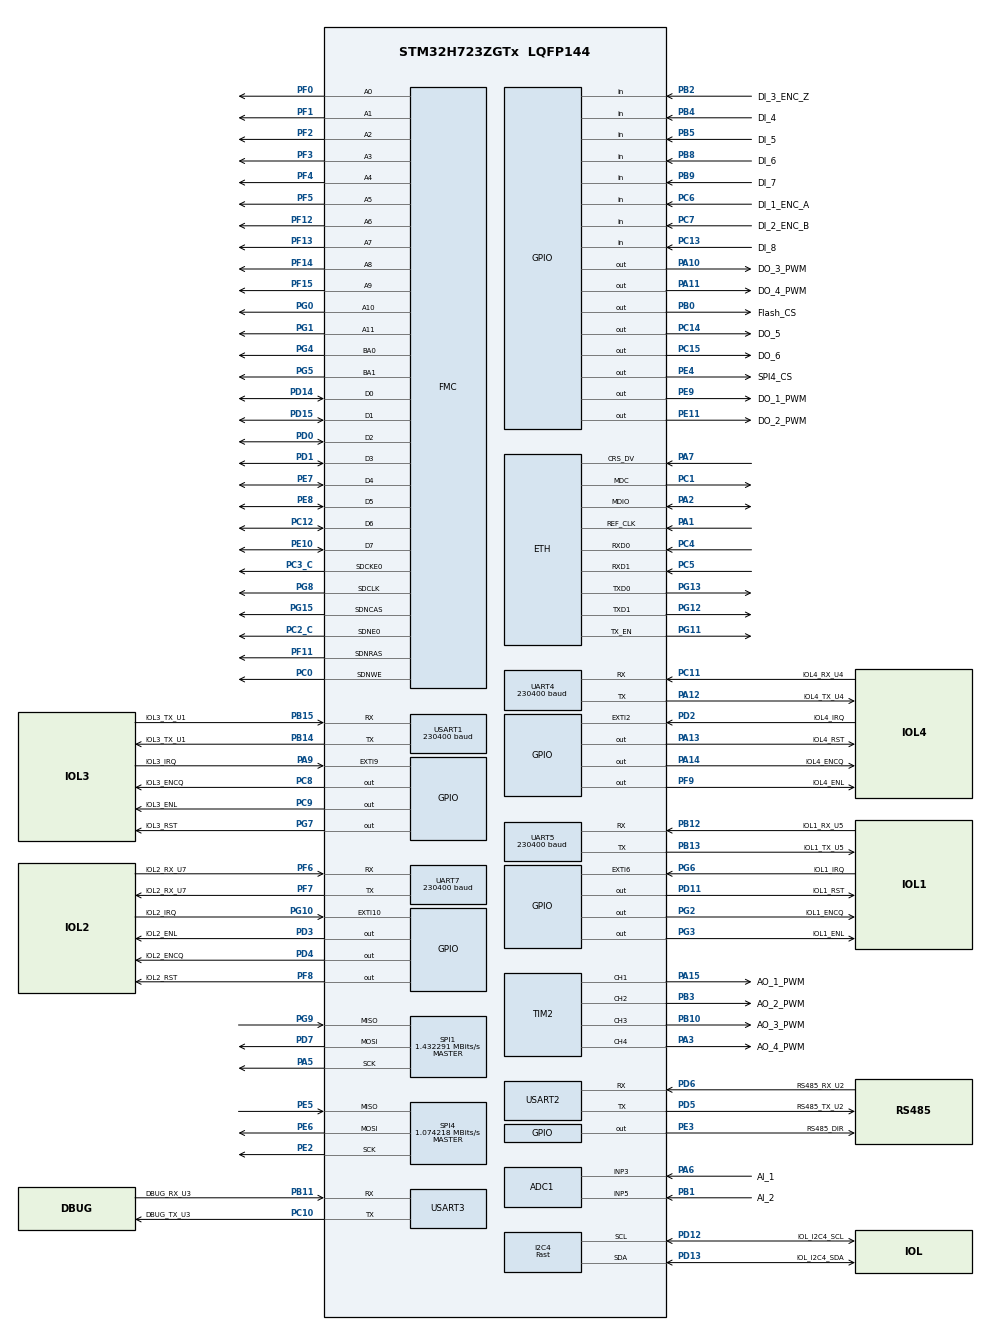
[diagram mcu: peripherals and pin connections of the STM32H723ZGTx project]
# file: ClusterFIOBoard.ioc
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ADC1.Channel-0\#ChannelRegularConversion=ADC_CHANNEL_3
ADC1.NbrOfConversionFlag=1
ADC1.OffsetNumber-0\#ChannelRegularConversion=ADC_OFFSET_NONE
ADC1.OffsetSignedSaturation-0\#ChannelRegularConversion=DISABLE
ADC1.Rank-0\#ChannelRegularConversion=1
ADC1.SamplingTime-0\#ChannelRegularConversion=ADC_SAMPLETIME_1CYCLE_5
ADC1.master=1
CORTEX_M7.CPU_DCache=Enabled
Dma.Request0=SPI4_TX
Dma.Request1=SPI4_RX
Dma.Request2=SPI1_TX
Dma.Request3=SPI1_RX
Dma.SPI1_RX.3.Direction=DMA_PERIPH_TO_MEMORY
Dma.SPI1_RX.3.EventEnable=DISABLE
Dma.SPI1_RX.3.FIFOMode=DMA_FIFOMODE_DISABLE
Dma.SPI1_RX.3.Instance=DMA1_Stream3
Dma.SPI1_RX.3.MemDataAlignment=DMA_MDATAALIGN_BYTE
Dma.SPI1_RX.3.MemInc=DMA_MINC_ENABLE
Dma.SPI1_RX.3.Mode=DMA_NORMAL
Dma.SPI1_RX.3.PeriphDataAlignment=DMA_PDATAALIGN_BYTE
Dma.SPI1_RX.3.PeriphInc=DMA_PINC_DISABLE
Dma.SPI1_RX.3.Polarity=HAL_DMAMUX_REQ_GEN_RISING
Dma.SPI1_RX.3.Priority=DMA_PRIORITY_HIGH
Dma.SPI1_RX.3.RequestNumber=1
Dma.SPI1_RX.3.SignalID=NONE
Dma.SPI1_RX.3.SyncEnable=DISABLE
Dma.SPI1_RX.3.SyncPolarity=HAL_DMAMUX_SYNC_NO_EVENT
Dma.SPI1_RX.3.SyncRequestNumber=1
Dma.SPI1_RX.3.SyncSignalID=NONE
Dma.SPI1_TX.2.Direction=DMA_MEMORY_TO_PERIPH
Dma.SPI1_TX.2.EventEnable=DISABLE
Dma.SPI1_TX.2.FIFOMode=DMA_FIFOMODE_DISABLE
Dma.SPI1_TX.2.Instance=DMA1_Stream2
Dma.SPI1_TX.2.MemDataAlignment=DMA_MDATAALIGN_BYTE
Dma.SPI1_TX.2.MemInc=DMA_MINC_ENABLE
Dma.SPI1_TX.2.Mode=DMA_NORMAL
Dma.SPI1_TX.2.PeriphDataAlignment=DMA_PDATAALIGN_BYTE
Dma.SPI1_TX.2.PeriphInc=DMA_PINC_DISABLE
Dma.SPI1_TX.2.Polarity=HAL_DMAMUX_REQ_GEN_RISING
Dma.SPI1_TX.2.Priority=DMA_PRIORITY_HIGH
Dma.SPI1_TX.2.RequestNumber=1
Dma.SPI1_TX.2.SignalID=NONE
Dma.SPI1_TX.2.SyncEnable=DISABLE
Dma.SPI1_TX.2.SyncPolarity=HAL_DMAMUX_SYNC_NO_EVENT
Dma.SPI1_TX.2.SyncRequestNumber=1
Dma.SPI1_TX.2.SyncSignalID=NONE
Dma.SPI4_RX.1.Direction=DMA_PERIPH_TO_MEMORY
Dma.SPI4_RX.1.EventEnable=DISABLE
Dma.SPI4_RX.1.FIFOMode=DMA_FIFOMODE_DISABLE
Dma.SPI4_RX.1.Instance=DMA2_Stream3
Dma.SPI4_RX.1.MemDataAlignment=DMA_MDATAALIGN_BYTE
Dma.SPI4_RX.1.MemInc=DMA_MINC_ENABLE
Dma.SPI4_RX.1.Mode=DMA_NORMAL
Dma.SPI4_RX.1.PeriphDataAlignment=DMA_PDATAALIGN_BYTE
Dma.SPI4_RX.1.PeriphInc=DMA_PINC_DISABLE
Dma.SPI4_RX.1.Polarity=HAL_DMAMUX_REQ_GEN_RISING
Dma.SPI4_RX.1.Priority=DMA_PRIORITY_HIGH
Dma.SPI4_RX.1.RequestNumber=1
Dma.SPI4_RX.1.SignalID=NONE
Dma.SPI4_RX.1.SyncEnable=DISABLE
Dma.SPI4_RX.1.SyncPolarity=HAL_DMAMUX_SYNC_NO_EVENT
Dma.SPI4_RX.1.SyncRequestNumber=1
Dma.SPI4_RX.1.SyncSignalID=NONE
Dma.SPI4_TX.0.Direction=DMA_MEMORY_TO_PERIPH
Dma.SPI4_TX.0.EventEnable=DISABLE
Dma.SPI4_TX.0.FIFOMode=DMA_FIFOMODE_DISABLE
Dma.SPI4_TX.0.Instance=DMA2_Stream1
Dma.SPI4_TX.0.MemDataAlignment=DMA_MDATAALIGN_BYTE
Dma.SPI4_TX.0.MemInc=DMA_MINC_ENABLE
Dma.SPI4_TX.0.Mode=DMA_NORMAL
Dma.SPI4_TX.0.PeriphDataAlignment=DMA_PDATAALIGN_BYTE
Dma.SPI4_TX.0.PeriphInc=DMA_PINC_DISABLE
Dma.SPI4_TX.0.Polarity=HAL_DMAMUX_REQ_GEN_RISING
Dma.SPI4_TX.0.Priority=DMA_PRIORITY_HIGH
Dma.SPI4_TX.0.RequestNumber=1
Dma.SPI4_TX.0.SignalID=NONE
Dma.SPI4_TX.0.SyncEnable=DISABLE
Dma.SPI4_TX.0.SyncPolarity=HAL_DMAMUX_SYNC_NO_EVENT
Dma.SPI4_TX.0.SyncRequestNumber=1
Dma.SPI4_TX.0.SyncSignalID=NONE
ETH.MediaInterface=HAL_ETH_RMII_MODE
FMC.BankMapConfig=FMC_SWAPBMAP_DISABLE
FMC.ReadBurst1=FMC_SDRAM_RBURST_ENABLE
FMC.ReadBurst2=FMC_SDRAM_RBURST_ENABLE
FMC.ReadPipeDelay1=FMC_SDRAM_RPIPE_DELAY_0
FMC.SDClockPeriod1=FMC_SDRAM_CLOCK_PERIOD_2
FMC.SDClockPeriod2=FMC_SDRAM_CLOCK_PERIOD_2
I2C4.I2C_Speed_Mode=I2C_Fast
I2C4.Timing=0x00D049FB
Mcu.Family=STM32H7
Mcu.Name=STM32H723ZGTx
Mcu.Package=LQFP144
NVIC.DMA1_Stream2_IRQn=true\:0\:0\:false\:false\:true\:false\:true\:true
NVIC.DMA1_Stream3_IRQn=true\:0\:0\:false\:false\:true\:false\:true\:true
NVIC.DMA2_Stream1_IRQn=true\:0\:0\:false\:false\:true\:false\:true\:true
NVIC.DMA2_Stream3_IRQn=true\:0\:0\:false\:false\:true\:false\:true\:true
NVIC.PriorityGroup=NVIC_PRIORITYGROUP_4
NVIC.SPI1_IRQn=true\:3\:0\:true\:false\:true\:true\:true\:true
NVIC.SPI4_IRQn=true\:3\:0\:true\:false\:true\:true\:true\:true
NVIC.UART4_IRQn=true\:0\:0\:false\:false\:true\:true\:true\:true
NVIC.UART5_IRQn=true\:0\:0\:false\:false\:true\:true\:true\:true
NVIC.UART7_IRQn=true\:0\:0\:false\:false\:true\:true\:true\:true
NVIC.USART1_IRQn=true\:0\:0\:false\:false\:true\:true\:true\:true
NVIC.USART2_IRQn=true\:0\:0\:false\:false\:true\:true\:true\:true
NVIC.USART3_IRQn=true\:0\:0\:false\:false\:true\:true\:true\:true
PA1.Mode=RMII
PA1.Signal=ETH_REF_CLK
PA10.GPIO_Label=DO_3_PWM
PA10.Signal=GPIO_Output
PA11.GPIO_Label=DO_4_PWM
PA11.Signal=GPIO_Output
PA12.GPIO_Label=IOL4_TX_U4
PA12.Mode=Asynchronous
PA12.Signal=UART4_TX
PA13(JTMS/SWDIO).GPIO_Label=IOL4_RST
PA13(JTMS/SWDIO).GPIO_ModeDefaultOutputPP=GPIO_MODE_OUTPUT_OD
PA13(JTMS/SWDIO).GPIO_PuPd=GPIO_NOPULL
PA13(JTMS/SWDIO).Signal=GPIO_Output
PA14(JTCK/SWCLK).GPIO_Label=IOL4_ENCQ
PA14(JTCK/SWCLK).GPIO_ModeDefaultOutputPP=GPIO_MODE_OUTPUT_OD
PA14(JTCK/SWCLK).GPIO_PuPd=GPIO_NOPULL
PA14(JTCK/SWCLK).Signal=GPIO_Output
PA15(JTDI).GPIO_Label=AO_1_PWM
PA15(JTDI).Signal=S_TIM2_CH1_ETR
PA2.Mode=RMII
PA2.Signal=ETH_MDIO
PA3.GPIO_Label=AO_4_PWM
PA3.Signal=S_TIM2_CH4
PA5.Mode=Full_Duplex_Master
PA5.Signal=SPI1_SCK
PA6.GPIO_Label=AI_1
PA6.Signal=ADCx_INP3
PA7.Mode=RMII
PA7.Signal=ETH_CRS_DV
PA9.GPIO_Label=IOL3_IRQ
PA9.Signal=GPXTI9
PB0.GPIO_Label=Flash_CS
PB0.PinState=GPIO_PIN_SET
PB0.Signal=GPIO_Output
PB1.GPIO_Label=AI_2
PB1.Signal=ADCx_INP5
PB10.GPIO_Label=AO_3_PWM
PB10.Signal=S_TIM2_CH3
PB11.GPIO_Label=DBUG_RX_U3
PB11.Mode=Asynchronous
PB11.Signal=USART3_RX
PB12.GPIO_Label=IOL1_RX_U5
PB12.Mode=Asynchronous
PB12.Signal=UART5_RX
PB13.GPIO_Label=IOL1_TX_U5
PB13.Mode=Asynchronous
PB13.Signal=UART5_TX
PB14.GPIO_Label=IOL3_TX_U1
PB14.Mode=Asynchronous
PB14.Signal=USART1_TX
PB15.GPIO_Label=IOL3_TX_U1
PB15.Mode=Asynchronous
PB15.Signal=USART1_RX
PB2.GPIO_Label=DI_3_ENC_Z
PB2.Signal=GPIO_Input
PB3(JTDO/TRACESWO).GPIO_Label=AO_2_PWM
PB3(JTDO/TRACESWO).Signal=S_TIM2_CH2
PB4(NJTRST).GPIO_Label=DI_4
PB4(NJTRST).Signal=GPIO_Input
PB5.GPIO_Label=DI_5
PB5.Signal=GPIO_Input
PB8.GPIO_Label=DI_6
PB8.Signal=GPIO_Input
PB9.GPIO_Label=DI_7
PB9.Signal=GPIO_Input
PC0.Signal=FMC_SDNWE
PC1.Mode=RMII
PC1.Signal=ETH_MDC
PC10.GPIO_Label=DBUG_TX_U3
PC10.Mode=Asynchronous
PC10.Signal=USART3_TX
PC11.GPIO_Label=IOL4_RX_U4
PC11.Mode=Asynchronous
PC11.Signal=UART4_RX
PC12.Signal=FMC_D6_DA6
PC13.GPIO_Label=DI_8
PC13.Signal=GPIO_Input
PC14-OSC32_IN.GPIO_Label=DO_5
PC14-OSC32_IN.Signal=GPIO_Output
PC15-OSC32_OUT.GPIO_Label=DO_6
PC15-OSC32_OUT.Signal=GPIO_Output
PC2_C.Mode=SdramChipSelect1_1
PC2_C.Signal=FMC_SDNE0
PC3_C.Mode=SdramChipSelect1_1
PC3_C.Signal=FMC_SDCKE0
PC4.Mode=RMII
PC4.Signal=ETH_RXD0
PC5.Mode=RMII
PC5.Signal=ETH_RXD1
PC6.GPIO_Label=DI_1_ENC_A
PC6.Signal=GPIO_Input
PC7.GPIO_Label=DI_2_ENC_B
PC7.Signal=GPIO_Input
PC8.GPIO_Label=IOL3_ENCQ
PC8.Signal=GPIO_Output
PC9.GPIO_Label=IOL3_ENL
PC9.Signal=GPIO_Output
PD0.Signal=FMC_D2_DA2
PD1.Signal=FMC_D3_DA3
PD11.GPIO_Label=IOL1_RST
PD11.GPIO_Speed=GPIO_SPEED_FREQ_VERY_HIGH
PD11.Signal=GPIO_Output
PD12.GPIO_Label=IOL_I2C4_SCL
PD12.Mode=I2C
PD12.Signal=I2C4_SCL
PD13.GPIO_Label=IOL_I2C4_SDA
PD13.Mode=I2C
PD13.Signal=I2C4_SDA
PD14.Signal=FMC_D0_DA0
PD15.Signal=FMC_D1_DA1
PD2.GPIO_Label=IOL4_IRQ
PD2.Signal=GPXTI2
PD3.GPIO_Label=IOL2_ENL
PD3.Signal=GPIO_Output
PD4.GPIO_Label=IOL2_ENCQ
PD4.Signal=GPIO_Output
PD5.GPIO_Label=RS485_TX_U2
PD5.Mode=Asynchronous
PD5.Signal=USART2_TX
PD6.GPIO_Label=RS485_RX_U2
PD6.Mode=Asynchronous
PD6.Signal=USART2_RX
PD7.Mode=Full_Duplex_Master
PD7.Signal=SPI1_MOSI
PE10.Signal=FMC_D7_DA7
PE11.GPIO_Label=DO_2_PWM
PE11.Signal=GPIO_Output
PE2.Mode=Full_Duplex_Master
PE2.Signal=SPI4_SCK
PE3.GPIO_Label=RS485_DIR
PE3.GPIO_Speed=GPIO_SPEED_FREQ_VERY_HIGH
PE3.Signal=GPIO_Output
PE4.GPIO_Label=SPI4_CS
PE4.GPIO_Speed=GPIO_SPEED_FREQ_HIGH
PE4.PinState=GPIO_PIN_SET
PE4.Signal=GPIO_Output
PE5.Mode=Full_Duplex_Master
PE5.Signal=SPI4_MISO
PE6.Mode=Full_Duplex_Master
PE6.Signal=SPI4_MOSI
PE7.Signal=FMC_D4_DA4
PE8.Signal=FMC_D5_DA5
PE9.GPIO_Label=DO_1_PWM
PE9.Signal=GPIO_Output
PF0.Signal=FMC_A0
PF1.Signal=FMC_A1
PF11.Signal=FMC_SDNRAS
PF12.Signal=FMC_A6
PF13.Signal=FMC_A7
PF14.Signal=FMC_A8
PF15.Signal=FMC_A9
PF2.Signal=FMC_A2
PF3.Signal=FMC_A3
PF4.Signal=FMC_A4
PF5.Signal=FMC_A5
PF6.GPIO_Label=IOL2_RX_U7
PF6.Mode=Asynchronous
PF6.Signal=UART7_RX
PF7.GPIO_Label=IOL2_RX_U7
PF7.Mode=Asynchronous
PF7.Signal=UART7_TX
PF8.GPIO_Label=IOL2_RST
PF8.Signal=GPIO_Output
PF9.GPIO_Label=IOL4_ENL
PF9.Signal=GPIO_Output
PG0.Signal=FMC_A10
PG1.Signal=FMC_A11
PG10.GPIO_Label=IOL2_IRQ
PG10.Signal=GPXTI10
PG11.Mode=RMII
PG11.Signal=ETH_TX_EN
PG12.Mode=RMII
PG12.Signal=ETH_TXD1
PG13.Mode=RMII
PG13.Signal=ETH_TXD0
PG15.Signal=FMC_SDNCAS
PG2.GPIO_Label=IOL1_ENCQ
PG2.Signal=GPIO_Output
PG3.GPIO_Label=IOL1_ENL
PG3.Signal=GPIO_Output
PG4.Signal=FMC_A14_BA0
PG5.Signal=FMC_A15_BA1
PG6.GPIO_Label=IOL1_IRQ
PG6.Signal=GPXTI6
PG7.GPIO_Label=IOL3_RST
PG7.Signal=GPIO_Output
PG8.Signal=FMC_SDCLK
PG9.Mode=Full_Duplex_Master
PG9.Signal=SPI1_MISO
ProjectManager.HeapSize=0x200
ProjectManager.StackSize=0x400
ProjectManager.TargetToolchain=STM32CubeIDE
RCC.ADCFreq_Value=96000000
RCC.APB1Freq_Value=137500000
RCC.APB2Freq_Value=137500000
RCC.APB3Freq_Value=137500000
RCC.APB4Freq_Value=137500000
RCC.CortexFreq_Value=550000000
RCC.D1PPRE=RCC_APB3_DIV2
RCC.D2PPRE1=RCC_APB1_DIV2
RCC.D2PPRE2=RCC_APB2_DIV2
RCC.D3PPRE=RCC_APB4_DIV2
RCC.DIVM1=4
RCC.DIVM2=4
RCC.DIVN1=34
RCC.DIVN2=12
RCC.DIVP1=1
RCC.DIVQ1=3
RCC.HCLKFreq_Value=275000000
RCC.HPRE=RCC_HCLK_DIV2
RCC.PLL2FRACN=0
RCC.PLL2_VCI_Range-AdvancedSettings=RCC_PLL2VCIRANGE_0
RCC.PLL2_VCO_SEL-AdvancedSettings=RCC_PLL2VCOMEDIUM
RCC.PLL3_VCO_SEL-AdvancedSettings=RCC_PLL3VCOMEDIUM
RCC.PLLFRACN=3072
RCC.SYSCLKFreq_VALUE=550000000
RCC.SYSCLKSource=RCC_SYSCLKSOURCE_PLLCLK
RCC.USBFreq_Value=183333333.33333334
SH.ADCx_INP3.0=ADC1_INP3,IN3-Single-Ended
SH.ADCx_INP5.0=ADC1_INP5,IN5-Single-Ended
SH.FMC_A0.0=FMC_A0,12b-sda1
SH.FMC_A1.0=FMC_A1,12b-sda1
SH.FMC_A10.0=FMC_A10,12b-sda1
SH.FMC_A11.0=FMC_A11,12b-sda1
SH.FMC_A14_BA0.0=FMC_BA0,FourSdramBanks1
SH.FMC_A15_BA1.0=FMC_BA1,FourSdramBanks1
SH.FMC_A2.0=FMC_A2,12b-sda1
SH.FMC_A3.0=FMC_A3,12b-sda1
SH.FMC_A4.0=FMC_A4,12b-sda1
SH.FMC_A5.0=FMC_A5,12b-sda1
SH.FMC_A6.0=FMC_A6,12b-sda1
SH.FMC_A7.0=FMC_A7,12b-sda1
SH.FMC_A8.0=FMC_A8,12b-sda1
SH.FMC_A9.0=FMC_A9,12b-sda1
SH.FMC_D0_DA0.0=FMC_D0,sd-8b-d1
SH.FMC_D1_DA1.0=FMC_D1,sd-8b-d1
SH.FMC_D2_DA2.0=FMC_D2,sd-8b-d1
SH.FMC_D3_DA3.0=FMC_D3,sd-8b-d1
SH.FMC_D4_DA4.0=FMC_D4,sd-8b-d1
SH.FMC_D5_DA5.0=FMC_D5,sd-8b-d1
SH.FMC_D6_DA6.0=FMC_D6,sd-8b-d1
SH.FMC_D7_DA7.0=FMC_D7,sd-8b-d1
SH.FMC_SDCLK.0=FMC_SDCLK,12b-sda1
SH.FMC_SDNCAS.0=FMC_SDNCAS,12b-sda1
SH.FMC_SDNRAS.0=FMC_SDNRAS,12b-sda1
SH.FMC_SDNWE.0=FMC_SDNWE,12b-sda1
SH.S_TIM2_CH1_ETR.0=TIM2_CH1,PWM Generation1 CH1
SH.S_TIM2_CH2.0=TIM2_CH2,PWM Generation2 CH2
SH.S_TIM2_CH3.0=TIM2_CH3,PWM Generation3 CH3
SH.S_TIM2_CH4.0=TIM2_CH4,PWM Generation4 CH4
SPI1.BaudRatePrescaler=SPI_BAUDRATEPRESCALER_128
SPI1.CalculateBaudRate=1.432291 MBits/s
SPI1.DataSize=SPI_DATASIZE_8BIT
SPI1.Direction=SPI_DIRECTION_2LINES
SPI1.Mode=SPI_MODE_MASTER
SPI1.VirtualType=VM_MASTER
SPI4.BaudRatePrescaler=SPI_BAUDRATEPRESCALER_128
SPI4.CalculateBaudRate=1.074218 MBits/s
SPI4.DataSize=SPI_DATASIZE_8BIT
SPI4.Direction=SPI_DIRECTION_2LINES
SPI4.Mode=SPI_MODE_MASTER
SPI4.VirtualType=VM_MASTER
TIM2.Channel-PWM\ Generation1\ CH1=TIM_CHANNEL_1
TIM2.Channel-PWM\ Generation2\ CH2=TIM_CHANNEL_2
TIM2.Channel-PWM\ Generation3\ CH3=TIM_CHANNEL_3
TIM2.Channel-PWM\ Generation4\ CH4=TIM_CHANNEL_4
UART4.BaudRate=230400
UART4.Parity=PARITY_EVEN
UART4.WordLength=WORDLENGTH_9B
UART5.BaudRate=230400
UART5.Parity=PARITY_EVEN
UART5.WordLength=WORDLENGTH_9B
UART7.BaudRate=230400
UART7.Parity=PARITY_EVEN
UART7.WordLength=WORDLENGTH_9B
USART1.BaudRate=230400
USART1.Parity=PARITY_EVEN
USART1.VirtualMode-Asynchronous=VM_ASYNC
USART1.WordLength=WORDLENGTH_9B
USART2.Parity=PARITY_NONE
USART2.VirtualMode-Asynchronous=VM_ASYNC
USART2.WordLength=WORDLENGTH_8B
USART3.VirtualMode-Asynchronous=VM_ASYNC
USART3.WordLength=WORDLENGTH_8B
VP_TIM1_VS_ClockSourceINT.Mode=Internal
VP_TIM2_VS_ClockSourceINT.Mode=Internal
board=custom

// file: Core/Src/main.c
/* USER CODE BEGIN Header */
/**
  ******************************************************************************
  * @file           : main.c
  * @brief          : Main program body
  ******************************************************************************
  * @attention
  *
  * Copyright (c) 2024 STMicroelectronics.
  * All rights reserved.
  *
  * This software is licensed under terms that can be found in the LICENSE file
  * in the root directory of this software component.
  * If no LICENSE file comes with this software, it is provided AS-IS.
  *
  ******************************************************************************
  */
/* USER CODE END Header */
#include "main.h"
#include "string.h"

/* USER CODE BEGIN Includes */
#include "W25Qxx.h"
#include <stdint.h>
#include "debug.h"
#include "ksz8863.h"
#include "ethernet.h"
#include "nic.h"
/* USER CODE END Includes */

#if defined ( __ICCARM__ ) /*!< IAR Compiler */

#pragma location=0x30000000
ETH_DMADescTypeDef  DMARxDscrTab[ETH_RX_DESC_CNT]; /* Ethernet Rx DMA Descriptors */
#pragma location=0x30000060
ETH_DMADescTypeDef  DMATxDscrTab[ETH_TX_DESC_CNT]; /* Ethernet Tx DMA Descriptors */
#pragma location=0x300000c0
uint8_t Rx_Buff[ETH_RX_DESC_CNT][ETH_MAX_PACKET_SIZE]; /* Ethernet Receive Buffers */

#elif defined ( __CC_ARM )  /* MDK ARM Compiler */

__attribute__((at(0x30000000))) ETH_DMADescTypeDef  DMARxDscrTab[ETH_RX_DESC_CNT]; /* Ethernet Rx DMA Descriptors */
__attribute__((at(0x30000060))) ETH_DMADescTypeDef  DMATxDscrTab[ETH_TX_DESC_CNT]; /* Ethernet Tx DMA Descriptors */
__attribute__((at(0x300000c0))) uint8_t Rx_Buff[ETH_RX_DESC_CNT][ETH_MAX_PACKET_SIZE]; /* Ethernet Receive Buffer */

#elif defined ( __GNUC__ ) /* GNU Compiler */

ETH_DMADescTypeDef DMARxDscrTab[ETH_RX_DESC_CNT] __attribute__((section(".RxDecripSection"))); /* Ethernet Rx DMA Descriptors */
ETH_DMADescTypeDef DMATxDscrTab[ETH_TX_DESC_CNT] __attribute__((section(".TxDecripSection")));   /* Ethernet Tx DMA Descriptors */
uint8_t Rx_Buff[ETH_RX_DESC_CNT][ETH_MAX_PACKET_SIZE] __attribute__((section(".RxArraySection"))); /* Ethernet Receive Buffers */

#endif

ETH_TxPacketConfig TxConfig;
ADC_HandleTypeDef hadc1;

ETH_HandleTypeDef heth;

I2C_HandleTypeDef hi2c4;

SPI_HandleTypeDef hspi1;
SPI_HandleTypeDef hspi4;
DMA_HandleTypeDef hdma_spi1_tx;
DMA_HandleTypeDef hdma_spi1_rx;
DMA_HandleTypeDef hdma_spi4_tx;
DMA_HandleTypeDef hdma_spi4_rx;

TIM_HandleTypeDef htim1;
TIM_HandleTypeDef htim2;

UART_HandleTypeDef huart4;
UART_HandleTypeDef huart5;
UART_HandleTypeDef huart7;
UART_HandleTypeDef huart1;
UART_HandleTypeDef huart2;
UART_HandleTypeDef huart3;

SDRAM_HandleTypeDef hsdram1;

void SystemClock_Config(void);
static void MX_GPIO_Init(void);
static void MX_DMA_Init(void);
static void MX_I2C4_Init(void);
static void MX_TIM1_Init(void);
static void MX_TIM2_Init(void);
static void MX_UART4_Init(void);
static void MX_UART5_Init(void);
static void MX_UART7_Init(void);
static void MX_USART1_UART_Init(void);
static void MX_USART2_UART_Init(void);
static void MX_FMC_Init(void);
static void MX_SPI1_Init(void);
static void MX_USART3_UART_Init(void);
static void MX_ADC1_Init(void);
static void MX_SPI4_Init(void);
static void MX_ETH_Init(void);

int main(void)
{

  /* Enable D-Cache---------------------------------------------------------*/
  SCB_EnableDCache();

  /* MCU Configuration--------------------------------------------------------*/

  /* Reset of all peripherals, Initializes the Flash interface and the Systick. */
  HAL_Init();

  /* Configure the system clock */
  SystemClock_Config();

  /* Initialize all configured peripherals */
  MX_GPIO_Init();
  MX_DMA_Init();
  MX_I2C4_Init();
  MX_TIM1_Init();
  MX_TIM2_Init();
  MX_UART4_Init();
  MX_UART5_Init();
  MX_UART7_Init();
  MX_USART1_UART_Init();
  MX_USART2_UART_Init();
  MX_FMC_Init();
  MX_SPI1_Init();
  MX_USART3_UART_Init();
  MX_ADC1_Init();
  MX_SPI4_Init();
  MX_ETH_Init();
  /* USER CODE BEGIN 2 */
  DebugPrintf("mahmudul\r\n");

  	uint32_t id2 = 0;

  	id2 =0;
	id2 = ksz_ReadID_DMA();
	DebugPrintf("ksz id2 DMA  is %X\r\n", id2);
	HAL_Delay(1000);

    id2 = ksz_ReadID();
    DebugPrintf("\r\n");
    DebugPrintf("ksz id2 is %X\r\n", id2);

  uint32_t id = 0;
  uint8_t RxData[4608];
  DebugPrintf("r1\r\n");
  W25Q_Reset_DMA();
//  W25Q_Reset();
//  HAL_Delay(500);
  DebugPrintf("r2\r\n");
  id = W25Q_ReadID();
  DebugPrintf("id is %X\r\n", id);
  id =0;
  id = W25Q_ReadID_DMA();
  DebugPrintf("dma id is %X\r\n", id);

  uint32_t test = 0xDEADBEEF;;
  DebugPrintf("test value %X\r\n", test);

  // init ksz8863
  ksz8863Init();

//  uint8_t id3 = 0;
//  id3 = ksz_Read();
//  DebugPrintf("\r\n");
//  DebugPrintf("ksz id3 is %X\r\n", id3);
//
//  ksz_write();
//
//  id3 = ksz_Read();
//   DebugPrintf("\r\n");
//   DebugPrintf("ksz id3 is %X\r\n", id3);

//   ksz8863ReadSwitchReg(0);
   ksz8863DumpSwitchReg();

//   uint8_t data = 0x80;
//   uint8_t address = 0x02;
//   ksz8863WriteSwitchReg( address, data);
//   ksz8863ReadSwitchReg(address);

//   ksz8863DumpSwitchReg();

   ksz8863GetLinkState(1);
   ksz8863GetLinkState(2);
   ksz8863GetLinkState(3);

   ksz8863GetLinkSpeed(1);
   ksz8863GetLinkSpeed(2);
   ksz8863GetLinkSpeed(3);
   ksz8863GetDuplexMode(1);
   ksz8863GetDuplexMode(2);
   ksz8863GetDuplexMode(3);

   ksz8863GetPortState(1);
   ksz8863GetPortState(2);

   ksz8863SetPortState(1,3);

   ksz8863GetPortState(1);
   ksz8863GetPortState(2);

   uint8_t powerMode;
   powerMode = ksz8863GetPowerManagementMode();
   DebugPrintf("power mode %d\r\n", powerMode);
   ksz8863SetPowerManagementMode(0);
   powerMode = ksz8863GetPowerManagementMode();
   DebugPrintf("power mode %d\r\n", powerMode);

   MacAddr mac = {0xAA, 0xBB, 0xCC, 0xDD, 0xEE, 0xFF};
   printMacAddrAsBytes(&mac);

   ksz8863GetSwitchMacAddr();
  //  ksz8863SetSwitchMacAddr(&mac);
  //  ksz8863GetSwitchMacAddr();

   MacAddr mac1 = {0xA9, 0xB4, 0xAB, 0x12, 0x23, 0xFF};
   MacAddr mac2 = {0xAC, 0xBD, 0x11, 0x22, 0x33, 0xFF};

  SwitchFdbEntry entry = {
      .macAddr = { .b = {0x11, 0x22, 0x33, 0x44, 0x55, 0x66} },
      .srcPort = 1,
      .destPorts = 0x1, // Example: Ports 1 and 2
      .override = true
  };

// ksz8863AddStaticFdbEntry(&entry);
//  ksz8863DeleteStaticFdbEntry(&entry);

//   flush static table
// ksz8863FlushStaticFdbTable();

   SwitchFdbEntry entry1;

//   DebugPrintf("--------------print all table-------------\n");
//  for(int p = 0; p <8 ; p++)
//  {
//	   ksz8863GetStaticFdbEntry(p, &entry);
//  }

   ksz8863GetDynamicFdbEntry(0, &entry1);
  printSwitchFdbEntry(&entry1);

//   ksz8863SetStation1MacAddr(&mac1);
//   ksz8863SetStation2MacAddr(&mac2);
//   ksz8863GetStation1MacAddr();
//   ksz8863GetStation2MacAddr();

  /* USER CODE END 2 */

  /* Infinite loop */
  /* USER CODE BEGIN WHILE */
  while (1)
  {
	//  MX_LWIP_Process();

//	  HAL_UART_Transmit(&huart3, data, 30, HAL_MAX_DELAY);
	  DebugPrintf("mahmudul \r\n");
	  HAL_Delay(500);

    /* USER CODE END WHILE */

  }
}

void SystemClock_Config(void)
{
  RCC_OscInitTypeDef RCC_OscInitStruct = {0};
  RCC_ClkInitTypeDef RCC_ClkInitStruct = {0};

  /** Supply configuration update enable
  */
  HAL_PWREx_ConfigSupply(PWR_LDO_SUPPLY);
  /** Configure the main internal regulator output voltage
  */
  __HAL_PWR_VOLTAGESCALING_CONFIG(PWR_REGULATOR_VOLTAGE_SCALE0);

  while(!__HAL_PWR_GET_FLAG(PWR_FLAG_VOSRDY)) {}
  /** Macro to configure the PLL clock source
  */
  __HAL_RCC_PLL_PLLSOURCE_CONFIG(RCC_PLLSOURCE_HSI);
  /** Initializes the RCC Oscillators according to the specified parameters
  * in the RCC_OscInitTypeDef structure.
  */
  RCC_OscInitStruct.OscillatorType = RCC_OSCILLATORTYPE_HSI;
  RCC_OscInitStruct.HSIState = RCC_HSI_DIV1;
  RCC_OscInitStruct.HSICalibrationValue = RCC_HSICALIBRATION_DEFAULT;
  RCC_OscInitStruct.PLL.PLLState = RCC_PLL_ON;
  RCC_OscInitStruct.PLL.PLLSource = RCC_PLLSOURCE_HSI;
  RCC_OscInitStruct.PLL.PLLM = 4;
  RCC_OscInitStruct.PLL.PLLN = 34;
  RCC_OscInitStruct.PLL.PLLP = 1;
  RCC_OscInitStruct.PLL.PLLQ = 3;
  RCC_OscInitStruct.PLL.PLLR = 2;
  RCC_OscInitStruct.PLL.PLLRGE = RCC_PLL1VCIRANGE_3;
  RCC_OscInitStruct.PLL.PLLVCOSEL = RCC_PLL1VCOWIDE;
  RCC_OscInitStruct.PLL.PLLFRACN = 3072;
  if (HAL_RCC_OscConfig(&RCC_OscInitStruct) != HAL_OK)
  {
    Error_Handler();
  }
  /** Initializes the CPU, AHB and APB buses clocks
  */
  RCC_ClkInitStruct.ClockType = RCC_CLOCKTYPE_HCLK|RCC_CLOCKTYPE_SYSCLK
                              |RCC_CLOCKTYPE_PCLK1|RCC_CLOCKTYPE_PCLK2
                              |RCC_CLOCKTYPE_D3PCLK1|RCC_CLOCKTYPE_D1PCLK1;
  RCC_ClkInitStruct.SYSCLKSource = RCC_SYSCLKSOURCE_PLLCLK;
  RCC_ClkInitStruct.SYSCLKDivider = RCC_SYSCLK_DIV1;
  RCC_ClkInitStruct.AHBCLKDivider = RCC_HCLK_DIV2;
  RCC_ClkInitStruct.APB3CLKDivider = RCC_APB3_DIV2;
  RCC_ClkInitStruct.APB1CLKDivider = RCC_APB1_DIV2;
  RCC_ClkInitStruct.APB2CLKDivider = RCC_APB2_DIV2;
  RCC_ClkInitStruct.APB4CLKDivider = RCC_APB4_DIV2;

  if (HAL_RCC_ClockConfig(&RCC_ClkInitStruct, FLASH_LATENCY_3) != HAL_OK)
  {
    Error_Handler();
  }
}

static void MX_ADC1_Init(void)
{

  ADC_MultiModeTypeDef multimode = {0};
  ADC_ChannelConfTypeDef sConfig = {0};

  /** Common config
  */
  hadc1.Instance = ADC1;
  hadc1.Init.ClockPrescaler = ADC_CLOCK_ASYNC_DIV1;
  hadc1.Init.Resolution = ADC_RESOLUTION_16B;
  hadc1.Init.ScanConvMode = ADC_SCAN_DISABLE;
  hadc1.Init.EOCSelection = ADC_EOC_SINGLE_CONV;
  hadc1.Init.LowPowerAutoWait = DISABLE;
  hadc1.Init.ContinuousConvMode = DISABLE;
  hadc1.Init.NbrOfConversion = 1;
  hadc1.Init.DiscontinuousConvMode = DISABLE;
  hadc1.Init.ExternalTrigConv = ADC_SOFTWARE_START;
  hadc1.Init.ExternalTrigConvEdge = ADC_EXTERNALTRIGCONVEDGE_NONE;
  hadc1.Init.ConversionDataManagement = ADC_CONVERSIONDATA_DR;
  hadc1.Init.Overrun = ADC_OVR_DATA_PRESERVED;
  hadc1.Init.LeftBitShift = ADC_LEFTBITSHIFT_NONE;
  hadc1.Init.OversamplingMode = DISABLE;
  if (HAL_ADC_Init(&hadc1) != HAL_OK)
  {
    Error_Handler();
  }
  /** Configure the ADC multi-mode
  */
  multimode.Mode = ADC_MODE_INDEPENDENT;
  if (HAL_ADCEx_MultiModeConfigChannel(&hadc1, &multimode) != HAL_OK)
  {
    Error_Handler();
  }
  /** Configure Regular Channel
  */
  sConfig.Channel = ADC_CHANNEL_3;
  sConfig.Rank = ADC_REGULAR_RANK_1;
  sConfig.SamplingTime = ADC_SAMPLETIME_1CYCLE_5;
  sConfig.SingleDiff = ADC_SINGLE_ENDED;
  sConfig.OffsetNumber = ADC_OFFSET_NONE;
  sConfig.Offset = 0;
  sConfig.OffsetSignedSaturation = DISABLE;
  if (HAL_ADC_ConfigChannel(&hadc1, &sConfig) != HAL_OK)
  {
    Error_Handler();
  }

}

static void MX_ETH_Init(void)
{

   static uint8_t MACAddr[6];

  heth.Instance = ETH;
  MACAddr[0] = 0x00;
  MACAddr[1] = 0x80;
  MACAddr[2] = 0xE1;
  MACAddr[3] = 0x00;
  MACAddr[4] = 0x00;
  MACAddr[5] = 0x00;
  heth.Init.MACAddr = &MACAddr[0];
  heth.Init.MediaInterface = HAL_ETH_RMII_MODE;
  heth.Init.TxDesc = DMATxDscrTab;
  heth.Init.RxDesc = DMARxDscrTab;
  heth.Init.RxBuffLen = 1524;

  if (HAL_ETH_Init(&heth) != HAL_OK)
  {
    Error_Handler();
  }

  memset(&TxConfig, 0 , sizeof(ETH_TxPacketConfig));
  TxConfig.Attributes = ETH_TX_PACKETS_FEATURES_CSUM | ETH_TX_PACKETS_FEATURES_CRCPAD;
  TxConfig.ChecksumCtrl = ETH_CHECKSUM_IPHDR_PAYLOAD_INSERT_PHDR_CALC;
  TxConfig.CRCPadCtrl = ETH_CRC_PAD_INSERT;

}

static void MX_I2C4_Init(void)
{

  hi2c4.Instance = I2C4;
  hi2c4.Init.Timing = 0x00D049FB;
  hi2c4.Init.OwnAddress1 = 0;
  hi2c4.Init.AddressingMode = I2C_ADDRESSINGMODE_7BIT;
  hi2c4.Init.DualAddressMode = I2C_DUALADDRESS_DISABLE;
  hi2c4.Init.OwnAddress2 = 0;
  hi2c4.Init.OwnAddress2Masks = I2C_OA2_NOMASK;
  hi2c4.Init.GeneralCallMode = I2C_GENERALCALL_DISABLE;
  hi2c4.Init.NoStretchMode = I2C_NOSTRETCH_DISABLE;
  if (HAL_I2C_Init(&hi2c4) != HAL_OK)
  {
    Error_Handler();
  }
  /** Configure Analogue filter
  */
  if (HAL_I2CEx_ConfigAnalogFilter(&hi2c4, I2C_ANALOGFILTER_ENABLE) != HAL_OK)
  {
    Error_Handler();
  }
  /** Configure Digital filter
  */
  if (HAL_I2CEx_ConfigDigitalFilter(&hi2c4, 0) != HAL_OK)
  {
    Error_Handler();
  }

}

static void MX_SPI1_Init(void)
{

  /* SPI1 parameter configuration*/
  hspi1.Instance = SPI1;
  hspi1.Init.Mode = SPI_MODE_MASTER;
  hspi1.Init.Direction = SPI_DIRECTION_2LINES;
  hspi1.Init.DataSize = SPI_DATASIZE_8BIT;
  hspi1.Init.CLKPolarity = SPI_POLARITY_LOW;
  hspi1.Init.CLKPhase = SPI_PHASE_1EDGE;
  hspi1.Init.NSS = SPI_NSS_SOFT;
  hspi1.Init.BaudRatePrescaler = SPI_BAUDRATEPRESCALER_128;
  hspi1.Init.FirstBit = SPI_FIRSTBIT_MSB;
  hspi1.Init.TIMode = SPI_TIMODE_DISABLE;
  hspi1.Init.CRCCalculation = SPI_CRCCALCULATION_DISABLE;
  hspi1.Init.CRCPolynomial = 0x0;
  hspi1.Init.NSSPMode = SPI_NSS_PULSE_ENABLE;
  hspi1.Init.NSSPolarity = SPI_NSS_POLARITY_LOW;
  hspi1.Init.FifoThreshold = SPI_FIFO_THRESHOLD_01DATA;
  hspi1.Init.TxCRCInitializationPattern = SPI_CRC_INITIALIZATION_ALL_ZERO_PATTERN;
  hspi1.Init.RxCRCInitializationPattern = SPI_CRC_INITIALIZATION_ALL_ZERO_PATTERN;
  hspi1.Init.MasterSSIdleness = SPI_MASTER_SS_IDLENESS_00CYCLE;
  hspi1.Init.MasterInterDataIdleness = SPI_MASTER_INTERDATA_IDLENESS_00CYCLE;
  hspi1.Init.MasterReceiverAutoSusp = SPI_MASTER_RX_AUTOSUSP_DISABLE;
  hspi1.Init.MasterKeepIOState = SPI_MASTER_KEEP_IO_STATE_DISABLE;
  hspi1.Init.IOSwap = SPI_IO_SWAP_DISABLE;
  if (HAL_SPI_Init(&hspi1) != HAL_OK)
  {
    Error_Handler();
  }

}

static void MX_SPI4_Init(void)
{

  /* SPI4 parameter configuration*/
  hspi4.Instance = SPI4;
  hspi4.Init.Mode = SPI_MODE_MASTER;
  hspi4.Init.Direction = SPI_DIRECTION_2LINES;
  hspi4.Init.DataSize = SPI_DATASIZE_8BIT;
  hspi4.Init.CLKPolarity = SPI_POLARITY_LOW;
  hspi4.Init.CLKPhase = SPI_PHASE_1EDGE;
  hspi4.Init.NSS = SPI_NSS_SOFT;
  hspi4.Init.BaudRatePrescaler = SPI_BAUDRATEPRESCALER_128;
  hspi4.Init.FirstBit = SPI_FIRSTBIT_MSB;
  hspi4.Init.TIMode = SPI_TIMODE_DISABLE;
  hspi4.Init.CRCCalculation = SPI_CRCCALCULATION_DISABLE;
  hspi4.Init.CRCPolynomial = 0x0;
  hspi4.Init.NSSPMode = SPI_NSS_PULSE_ENABLE;
  hspi4.Init.NSSPolarity = SPI_NSS_POLARITY_LOW;
  hspi4.Init.FifoThreshold = SPI_FIFO_THRESHOLD_01DATA;
  hspi4.Init.TxCRCInitializationPattern = SPI_CRC_INITIALIZATION_ALL_ZERO_PATTERN;
  hspi4.Init.RxCRCInitializationPattern = SPI_CRC_INITIALIZATION_ALL_ZERO_PATTERN;
  hspi4.Init.MasterSSIdleness = SPI_MASTER_SS_IDLENESS_00CYCLE;
  hspi4.Init.MasterInterDataIdleness = SPI_MASTER_INTERDATA_IDLENESS_00CYCLE;
  hspi4.Init.MasterReceiverAutoSusp = SPI_MASTER_RX_AUTOSUSP_DISABLE;
  hspi4.Init.MasterKeepIOState = SPI_MASTER_KEEP_IO_STATE_DISABLE;
  hspi4.Init.IOSwap = SPI_IO_SWAP_DISABLE;
  if (HAL_SPI_Init(&hspi4) != HAL_OK)
  {
    Error_Handler();
  }

}

static void MX_TIM1_Init(void)
{

  TIM_ClockConfigTypeDef sClockSourceConfig = {0};
  TIM_MasterConfigTypeDef sMasterConfig = {0};

  htim1.Instance = TIM1;
  htim1.Init.Prescaler = 0;
  htim1.Init.CounterMode = TIM_COUNTERMODE_UP;
  htim1.Init.Period = 65535;
  htim1.Init.ClockDivision = TIM_CLOCKDIVISION_DIV1;
  htim1.Init.RepetitionCounter = 0;
  htim1.Init.AutoReloadPreload = TIM_AUTORELOAD_PRELOAD_DISABLE;
  if (HAL_TIM_Base_Init(&htim1) != HAL_OK)
  {
    Error_Handler();
  }
  sClockSourceConfig.ClockSource = TIM_CLOCKSOURCE_INTERNAL;
  if (HAL_TIM_ConfigClockSource(&htim1, &sClockSourceConfig) != HAL_OK)
  {
    Error_Handler();
  }
  sMasterConfig.MasterOutputTrigger = TIM_TRGO_RESET;
  sMasterConfig.MasterOutputTrigger2 = TIM_TRGO2_RESET;
  sMasterConfig.MasterSlaveMode = TIM_MASTERSLAVEMODE_DISABLE;
  if (HAL_TIMEx_MasterConfigSynchronization(&htim1, &sMasterConfig) != HAL_OK)
  {
    Error_Handler();
  }

}

static void MX_TIM2_Init(void)
{

  TIM_ClockConfigTypeDef sClockSourceConfig = {0};
  TIM_MasterConfigTypeDef sMasterConfig = {0};
  TIM_OC_InitTypeDef sConfigOC = {0};

  htim2.Instance = TIM2;
  htim2.Init.Prescaler = 0;
  htim2.Init.CounterMode = TIM_COUNTERMODE_UP;
  htim2.Init.Period = 4294967295;
  htim2.Init.ClockDivision = TIM_CLOCKDIVISION_DIV1;
  htim2.Init.AutoReloadPreload = TIM_AUTORELOAD_PRELOAD_DISABLE;
  if (HAL_TIM_Base_Init(&htim2) != HAL_OK)
  {
    Error_Handler();
  }
  sClockSourceConfig.ClockSource = TIM_CLOCKSOURCE_INTERNAL;
  if (HAL_TIM_ConfigClockSource(&htim2, &sClockSourceConfig) != HAL_OK)
  {
    Error_Handler();
  }
  if (HAL_TIM_PWM_Init(&htim2) != HAL_OK)
  {
    Error_Handler();
  }
  sMasterConfig.MasterOutputTrigger = TIM_TRGO_RESET;
  sMasterConfig.MasterSlaveMode = TIM_MASTERSLAVEMODE_DISABLE;
  if (HAL_TIMEx_MasterConfigSynchronization(&htim2, &sMasterConfig) != HAL_OK)
  {
    Error_Handler();
  }
  sConfigOC.OCMode = TIM_OCMODE_PWM1;
  sConfigOC.Pulse = 0;
  sConfigOC.OCPolarity = TIM_OCPOLARITY_HIGH;
  sConfigOC.OCFastMode = TIM_OCFAST_DISABLE;
  if (HAL_TIM_PWM_ConfigChannel(&htim2, &sConfigOC, TIM_CHANNEL_1) != HAL_OK)
  {
    Error_Handler();
  }
  if (HAL_TIM_PWM_ConfigChannel(&htim2, &sConfigOC, TIM_CHANNEL_2) != HAL_OK)
  {
    Error_Handler();
  }
  if (HAL_TIM_PWM_ConfigChannel(&htim2, &sConfigOC, TIM_CHANNEL_3) != HAL_OK)
  {
    Error_Handler();
  }
  if (HAL_TIM_PWM_ConfigChannel(&htim2, &sConfigOC, TIM_CHANNEL_4) != HAL_OK)
  {
    Error_Handler();
  }
  HAL_TIM_MspPostInit(&htim2);

}

static void MX_UART4_Init(void)
{

  huart4.Instance = UART4;
  huart4.Init.BaudRate = 230400;
  huart4.Init.WordLength = UART_WORDLENGTH_9B;
  huart4.Init.StopBits = UART_STOPBITS_1;
  huart4.Init.Parity = UART_PARITY_EVEN;
  huart4.Init.Mode = UART_MODE_TX_RX;
  huart4.Init.HwFlowCtl = UART_HWCONTROL_NONE;
  huart4.Init.OverSampling = UART_OVERSAMPLING_16;
  huart4.Init.OneBitSampling = UART_ONE_BIT_SAMPLE_DISABLE;
  huart4.Init.ClockPrescaler = UART_PRESCALER_DIV1;
  huart4.AdvancedInit.AdvFeatureInit = UART_ADVFEATURE_NO_INIT;
  if (HAL_UART_Init(&huart4) != HAL_OK)
  {
    Error_Handler();
  }
  if (HAL_UARTEx_SetTxFifoThreshold(&huart4, UART_TXFIFO_THRESHOLD_1_8) != HAL_OK)
  {
    Error_Handler();
  }
  if (HAL_UARTEx_SetRxFifoThreshold(&huart4, UART_RXFIFO_THRESHOLD_1_8) != HAL_OK)
  {
    Error_Handler();
  }
  if (HAL_UARTEx_DisableFifoMode(&huart4) != HAL_OK)
  {
    Error_Handler();
  }

}

static void MX_UART5_Init(void)
{

  huart5.Instance = UART5;
  huart5.Init.BaudRate = 230400;
  huart5.Init.WordLength = UART_WORDLENGTH_9B;
  huart5.Init.StopBits = UART_STOPBITS_1;
  huart5.Init.Parity = UART_PARITY_EVEN;
  huart5.Init.Mode = UART_MODE_TX_RX;
  huart5.Init.HwFlowCtl = UART_HWCONTROL_NONE;
  huart5.Init.OverSampling = UART_OVERSAMPLING_16;
  huart5.Init.OneBitSampling = UART_ONE_BIT_SAMPLE_DISABLE;
  huart5.Init.ClockPrescaler = UART_PRESCALER_DIV1;
  huart5.AdvancedInit.AdvFeatureInit = UART_ADVFEATURE_NO_INIT;
  if (HAL_UART_Init(&huart5) != HAL_OK)
  {
    Error_Handler();
  }
  if (HAL_UARTEx_SetTxFifoThreshold(&huart5, UART_TXFIFO_THRESHOLD_1_8) != HAL_OK)
  {
    Error_Handler();
  }
  if (HAL_UARTEx_SetRxFifoThreshold(&huart5, UART_RXFIFO_THRESHOLD_1_8) != HAL_OK)
  {
    Error_Handler();
  }
  if (HAL_UARTEx_DisableFifoMode(&huart5) != HAL_OK)
  {
    Error_Handler();
  }

}

static void MX_UART7_Init(void)
{

  huart7.Instance = UART7;
  huart7.Init.BaudRate = 230400;
  huart7.Init.WordLength = UART_WORDLENGTH_9B;
  huart7.Init.StopBits = UART_STOPBITS_1;
  huart7.Init.Parity = UART_PARITY_EVEN;
  huart7.Init.Mode = UART_MODE_TX_RX;
  huart7.Init.HwFlowCtl = UART_HWCONTROL_NONE;
  huart7.Init.OverSampling = UART_OVERSAMPLING_16;
  huart7.Init.OneBitSampling = UART_ONE_BIT_SAMPLE_DISABLE;
  huart7.Init.ClockPrescaler = UART_PRESCALER_DIV1;
  huart7.AdvancedInit.AdvFeatureInit = UART_ADVFEATURE_NO_INIT;
  if (HAL_UART_Init(&huart7) != HAL_OK)
  {
    Error_Handler();
  }
  if (HAL_UARTEx_SetTxFifoThreshold(&huart7, UART_TXFIFO_THRESHOLD_1_8) != HAL_OK)
  {
    Error_Handler();
  }
  if (HAL_UARTEx_SetRxFifoThreshold(&huart7, UART_RXFIFO_THRESHOLD_1_8) != HAL_OK)
  {
    Error_Handler();
  }
  if (HAL_UARTEx_DisableFifoMode(&huart7) != HAL_OK)
  {
    Error_Handler();
  }

}

static void MX_USART1_UART_Init(void)
{

  huart1.Instance = USART1;
  huart1.Init.BaudRate = 230400;
  huart1.Init.WordLength = UART_WORDLENGTH_9B;
  huart1.Init.StopBits = UART_STOPBITS_1;
  huart1.Init.Parity = UART_PARITY_EVEN;
  huart1.Init.Mode = UART_MODE_TX_RX;
  huart1.Init.HwFlowCtl = UART_HWCONTROL_NONE;
  huart1.Init.OverSampling = UART_OVERSAMPLING_16;
  huart1.Init.OneBitSampling = UART_ONE_BIT_SAMPLE_DISABLE;
  huart1.Init.ClockPrescaler = UART_PRESCALER_DIV1;
  huart1.AdvancedInit.AdvFeatureInit = UART_ADVFEATURE_NO_INIT;
  if (HAL_UART_Init(&huart1) != HAL_OK)
  {
    Error_Handler();
  }
  if (HAL_UARTEx_SetTxFifoThreshold(&huart1, UART_TXFIFO_THRESHOLD_1_8) != HAL_OK)
  {
    Error_Handler();
  }
  if (HAL_UARTEx_SetRxFifoThreshold(&huart1, UART_RXFIFO_THRESHOLD_1_8) != HAL_OK)
  {
    Error_Handler();
  }
  if (HAL_UARTEx_DisableFifoMode(&huart1) != HAL_OK)
  {
    Error_Handler();
  }

}

static void MX_USART2_UART_Init(void)
{

  huart2.Instance = USART2;
  huart2.Init.BaudRate = 115200;
  huart2.Init.WordLength = UART_WORDLENGTH_8B;
  huart2.Init.StopBits = UART_STOPBITS_1;
  huart2.Init.Parity = UART_PARITY_NONE;
  huart2.Init.Mode = UART_MODE_TX_RX;
  huart2.Init.HwFlowCtl = UART_HWCONTROL_NONE;
  huart2.Init.OverSampling = UART_OVERSAMPLING_16;
  huart2.Init.OneBitSampling = UART_ONE_BIT_SAMPLE_DISABLE;
  huart2.Init.ClockPrescaler = UART_PRESCALER_DIV1;
  huart2.AdvancedInit.AdvFeatureInit = UART_ADVFEATURE_NO_INIT;
  if (HAL_UART_Init(&huart2) != HAL_OK)
  {
    Error_Handler();
  }
  if (HAL_UARTEx_SetTxFifoThreshold(&huart2, UART_TXFIFO_THRESHOLD_1_8) != HAL_OK)
  {
    Error_Handler();
  }
  if (HAL_UARTEx_SetRxFifoThreshold(&huart2, UART_RXFIFO_THRESHOLD_1_8) != HAL_OK)
  {
    Error_Handler();
  }
  if (HAL_UARTEx_DisableFifoMode(&huart2) != HAL_OK)
  {
    Error_Handler();
  }

}

static void MX_USART3_UART_Init(void)
{

  huart3.Instance = USART3;
  huart3.Init.BaudRate = 115200;
  huart3.Init.WordLength = UART_WORDLENGTH_8B;
  huart3.Init.StopBits = UART_STOPBITS_1;
  huart3.Init.Parity = UART_PARITY_NONE;
  huart3.Init.Mode = UART_MODE_TX_RX;
  huart3.Init.HwFlowCtl = UART_HWCONTROL_NONE;
  huart3.Init.OverSampling = UART_OVERSAMPLING_16;
  huart3.Init.OneBitSampling = UART_ONE_BIT_SAMPLE_DISABLE;
  huart3.Init.ClockPrescaler = UART_PRESCALER_DIV1;
  huart3.AdvancedInit.AdvFeatureInit = UART_ADVFEATURE_NO_INIT;
  if (HAL_UART_Init(&huart3) != HAL_OK)
  {
    Error_Handler();
  }
  if (HAL_UARTEx_SetTxFifoThreshold(&huart3, UART_TXFIFO_THRESHOLD_1_8) != HAL_OK)
  {
    Error_Handler();
  }
  if (HAL_UARTEx_SetRxFifoThreshold(&huart3, UART_RXFIFO_THRESHOLD_1_8) != HAL_OK)
  {
    Error_Handler();
  }
  if (HAL_UARTEx_DisableFifoMode(&huart3) != HAL_OK)
  {
    Error_Handler();
  }

}

static void MX_DMA_Init(void)
{

  /* DMA controller clock enable */
  __HAL_RCC_DMA2_CLK_ENABLE();
  __HAL_RCC_DMA1_CLK_ENABLE();

  /* DMA interrupt init */
  /* DMA1_Stream2_IRQn interrupt configuration */
  HAL_NVIC_SetPriority(DMA1_Stream2_IRQn, 0, 0);
  HAL_NVIC_EnableIRQ(DMA1_Stream2_IRQn);
  /* DMA1_Stream3_IRQn interrupt configuration */
  HAL_NVIC_SetPriority(DMA1_Stream3_IRQn, 0, 0);
  HAL_NVIC_EnableIRQ(DMA1_Stream3_IRQn);
  /* DMA2_Stream1_IRQn interrupt configuration */
  HAL_NVIC_SetPriority(DMA2_Stream1_IRQn, 0, 0);
  HAL_NVIC_EnableIRQ(DMA2_Stream1_IRQn);
  /* DMA2_Stream3_IRQn interrupt configuration */
  HAL_NVIC_SetPriority(DMA2_Stream3_IRQn, 0, 0);
  HAL_NVIC_EnableIRQ(DMA2_Stream3_IRQn);

}

/* FMC initialization function */
static void MX_FMC_Init(void)
{

  FMC_SDRAM_TimingTypeDef SdramTiming = {0};

  /** Perform the SDRAM1 memory initialization sequence
  */
  hsdram1.Instance = FMC_SDRAM_DEVICE;
  /* hsdram1.Init */
  hsdram1.Init.SDBank = FMC_SDRAM_BANK1;
  hsdram1.Init.ColumnBitsNumber = FMC_SDRAM_COLUMN_BITS_NUM_8;
  hsdram1.Init.RowBitsNumber = FMC_SDRAM_ROW_BITS_NUM_12;
  hsdram1.Init.MemoryDataWidth = FMC_SDRAM_MEM_BUS_WIDTH_8;
  hsdram1.Init.InternalBankNumber = FMC_SDRAM_INTERN_BANKS_NUM_4;
  hsdram1.Init.CASLatency = FMC_SDRAM_CAS_LATENCY_1;
  hsdram1.Init.WriteProtection = FMC_SDRAM_WRITE_PROTECTION_DISABLE;
  hsdram1.Init.SDClockPeriod = FMC_SDRAM_CLOCK_PERIOD_2;
  hsdram1.Init.ReadBurst = FMC_SDRAM_RBURST_ENABLE;
  hsdram1.Init.ReadPipeDelay = FMC_SDRAM_RPIPE_DELAY_0;
  /* SdramTiming */
  SdramTiming.LoadToActiveDelay = 16;
  SdramTiming.ExitSelfRefreshDelay = 16;
  SdramTiming.SelfRefreshTime = 16;
  SdramTiming.RowCycleDelay = 16;
  SdramTiming.WriteRecoveryTime = 16;
  SdramTiming.RPDelay = 16;
  SdramTiming.RCDDelay = 16;

  if (HAL_SDRAM_Init(&hsdram1, &SdramTiming) != HAL_OK)
  {
    Error_Handler( );
  }

}

static void MX_GPIO_Init(void)
{
  GPIO_InitTypeDef GPIO_InitStruct = {0};

  /* GPIO Ports Clock Enable */
  __HAL_RCC_GPIOE_CLK_ENABLE();
  __HAL_RCC_GPIOC_CLK_ENABLE();
  __HAL_RCC_GPIOF_CLK_ENABLE();
  __HAL_RCC_GPIOA_CLK_ENABLE();
  __HAL_RCC_GPIOB_CLK_ENABLE();
  __HAL_RCC_GPIOG_CLK_ENABLE();
  __HAL_RCC_GPIOD_CLK_ENABLE();

  /*Configure GPIO pin Output Level */
  HAL_GPIO_WritePin(GPIOE, RS485_DIR_Pin|DO_1_PWM_Pin|DO_2_PWM_Pin, GPIO_PIN_RESET);

  /*Configure GPIO pin Output Level */
  HAL_GPIO_WritePin(SPI4_CS_GPIO_Port, SPI4_CS_Pin, GPIO_PIN_SET);

  /*Configure GPIO pin Output Level */
  HAL_GPIO_WritePin(GPIOC, DO_5_Pin|DO_6_Pin|IOL3_ENCQ_Pin|IOL3_ENL_Pin, GPIO_PIN_RESET);

  /*Configure GPIO pin Output Level */
  HAL_GPIO_WritePin(GPIOF, IOL2_RST_Pin|IOL4_ENL_Pin, GPIO_PIN_RESET);

  /*Configure GPIO pin Output Level */
  HAL_GPIO_WritePin(Flash_CS_GPIO_Port, Flash_CS_Pin, GPIO_PIN_SET);

  /*Configure GPIO pin Output Level */
  HAL_GPIO_WritePin(GPIOD, IOL1_RST_Pin|IOL2_ENL_Pin|IOL2_ENCQ_Pin, GPIO_PIN_RESET);

  /*Configure GPIO pin Output Level */
  HAL_GPIO_WritePin(GPIOG, IOL1_ENCQ_Pin|IOL1_ENL_Pin|IOL3_RST_Pin, GPIO_PIN_RESET);

  /*Configure GPIO pin Output Level */
  HAL_GPIO_WritePin(GPIOA, DO_3_PWM_Pin|DO_4_PWM_Pin|IOL4_RST_Pin|IOL4_ENCQ_Pin, GPIO_PIN_RESET);

  /*Configure GPIO pin : RS485_DIR_Pin */
  GPIO_InitStruct.Pin = RS485_DIR_Pin;
  GPIO_InitStruct.Mode = GPIO_MODE_OUTPUT_PP;
  GPIO_InitStruct.Pull = GPIO_NOPULL;
  GPIO_InitStruct.Speed = GPIO_SPEED_FREQ_VERY_HIGH;
  HAL_GPIO_Init(RS485_DIR_GPIO_Port, &GPIO_InitStruct);

  /*Configure GPIO pin : SPI4_CS_Pin */
  GPIO_InitStruct.Pin = SPI4_CS_Pin;
  GPIO_InitStruct.Mode = GPIO_MODE_OUTPUT_PP;
  GPIO_InitStruct.Pull = GPIO_NOPULL;
  GPIO_InitStruct.Speed = GPIO_SPEED_FREQ_HIGH;
  HAL_GPIO_Init(SPI4_CS_GPIO_Port, &GPIO_InitStruct);

  /*Configure GPIO pins : DI_8_Pin DI_1_ENC_A_Pin DI_2_ENC_B_Pin */
  GPIO_InitStruct.Pin = DI_8_Pin|DI_1_ENC_A_Pin|DI_2_ENC_B_Pin;
  GPIO_InitStruct.Mode = GPIO_MODE_INPUT;
  GPIO_InitStruct.Pull = GPIO_NOPULL;
  HAL_GPIO_Init(GPIOC, &GPIO_InitStruct);

  /*Configure GPIO pins : DO_5_Pin DO_6_Pin IOL3_ENCQ_Pin IOL3_ENL_Pin */
  GPIO_InitStruct.Pin = DO_5_Pin|DO_6_Pin|IOL3_ENCQ_Pin|IOL3_ENL_Pin;
  GPIO_InitStruct.Mode = GPIO_MODE_OUTPUT_PP;
  GPIO_InitStruct.Pull = GPIO_NOPULL;
  GPIO_InitStruct.Speed = GPIO_SPEED_FREQ_LOW;
  HAL_GPIO_Init(GPIOC, &GPIO_InitStruct);

  /*Configure GPIO pins : IOL2_RST_Pin IOL4_ENL_Pin */
  GPIO_InitStruct.Pin = IOL2_RST_Pin|IOL4_ENL_Pin;
  GPIO_InitStruct.Mode = GPIO_MODE_OUTPUT_PP;
  GPIO_InitStruct.Pull = GPIO_NOPULL;
  GPIO_InitStruct.Speed = GPIO_SPEED_FREQ_LOW;
  HAL_GPIO_Init(GPIOF, &GPIO_InitStruct);

  /*Configure GPIO pin : Flash_CS_Pin */
  GPIO_InitStruct.Pin = Flash_CS_Pin;
  GPIO_InitStruct.Mode = GPIO_MODE_OUTPUT_PP;
  GPIO_InitStruct.Pull = GPIO_NOPULL;
  GPIO_InitStruct.Speed = GPIO_SPEED_FREQ_LOW;
  HAL_GPIO_Init(Flash_CS_GPIO_Port, &GPIO_InitStruct);

  /*Configure GPIO pins : DI_3_ENC_Z_Pin DI_4_Pin DI_5_Pin DI_6_Pin
                           DI_7_Pin */
  GPIO_InitStruct.Pin = DI_3_ENC_Z_Pin|DI_4_Pin|DI_5_Pin|DI_6_Pin
                          |DI_7_Pin;
  GPIO_InitStruct.Mode = GPIO_MODE_INPUT;
  GPIO_InitStruct.Pull = GPIO_NOPULL;
  HAL_GPIO_Init(GPIOB, &GPIO_InitStruct);

  /*Configure GPIO pins : DO_1_PWM_Pin DO_2_PWM_Pin */
  GPIO_InitStruct.Pin = DO_1_PWM_Pin|DO_2_PWM_Pin;
  GPIO_InitStruct.Mode = GPIO_MODE_OUTPUT_PP;
  GPIO_InitStruct.Pull = GPIO_NOPULL;
  GPIO_InitStruct.Speed = GPIO_SPEED_FREQ_LOW;
  HAL_GPIO_Init(GPIOE, &GPIO_InitStruct);

  /*Configure GPIO pin : IOL1_RST_Pin */
  GPIO_InitStruct.Pin = IOL1_RST_Pin;
  GPIO_InitStruct.Mode = GPIO_MODE_OUTPUT_PP;
  GPIO_InitStruct.Pull = GPIO_NOPULL;
  GPIO_InitStruct.Speed = GPIO_SPEED_FREQ_VERY_HIGH;
  HAL_GPIO_Init(IOL1_RST_GPIO_Port, &GPIO_InitStruct);

  /*Configure GPIO pins : IOL1_ENCQ_Pin IOL1_ENL_Pin IOL3_RST_Pin */
  GPIO_InitStruct.Pin = IOL1_ENCQ_Pin|IOL1_ENL_Pin|IOL3_RST_Pin;
  GPIO_InitStruct.Mode = GPIO_MODE_OUTPUT_PP;
  GPIO_InitStruct.Pull = GPIO_NOPULL;
  GPIO_InitStruct.Speed = GPIO_SPEED_FREQ_LOW;
  HAL_GPIO_Init(GPIOG, &GPIO_InitStruct);

  /*Configure GPIO pins : IOL1_IRQ_Pin IOL2_IRQ_Pin */
  GPIO_InitStruct.Pin = IOL1_IRQ_Pin|IOL2_IRQ_Pin;
  GPIO_InitStruct.Mode = GPIO_MODE_IT_RISING;
  GPIO_InitStruct.Pull = GPIO_NOPULL;
  HAL_GPIO_Init(GPIOG, &GPIO_InitStruct);

  /*Configure GPIO pin : IOL3_IRQ_Pin */
  GPIO_InitStruct.Pin = IOL3_IRQ_Pin;
  GPIO_InitStruct.Mode = GPIO_MODE_IT_RISING;
  GPIO_InitStruct.Pull = GPIO_NOPULL;
  HAL_GPIO_Init(IOL3_IRQ_GPIO_Port, &GPIO_InitStruct);

  /*Configure GPIO pins : DO_3_PWM_Pin DO_4_PWM_Pin */
  GPIO_InitStruct.Pin = DO_3_PWM_Pin|DO_4_PWM_Pin;
  GPIO_InitStruct.Mode = GPIO_MODE_OUTPUT_PP;
  GPIO_InitStruct.Pull = GPIO_NOPULL;
  GPIO_InitStruct.Speed = GPIO_SPEED_FREQ_LOW;
  HAL_GPIO_Init(GPIOA, &GPIO_InitStruct);

  /*Configure GPIO pins : IOL4_RST_Pin IOL4_ENCQ_Pin */
  GPIO_InitStruct.Pin = IOL4_RST_Pin|IOL4_ENCQ_Pin;
  GPIO_InitStruct.Mode = GPIO_MODE_OUTPUT_OD;
  GPIO_InitStruct.Pull = GPIO_NOPULL;
  GPIO_InitStruct.Speed = GPIO_SPEED_FREQ_LOW;
  HAL_GPIO_Init(GPIOA, &GPIO_InitStruct);

  /*Configure GPIO pin : IOL4_IRQ_Pin */
  GPIO_InitStruct.Pin = IOL4_IRQ_Pin;
  GPIO_InitStruct.Mode = GPIO_MODE_IT_RISING;
  GPIO_InitStruct.Pull = GPIO_NOPULL;
  HAL_GPIO_Init(IOL4_IRQ_GPIO_Port, &GPIO_InitStruct);

  /*Configure GPIO pins : IOL2_ENL_Pin IOL2_ENCQ_Pin */
  GPIO_InitStruct.Pin = IOL2_ENL_Pin|IOL2_ENCQ_Pin;
  GPIO_InitStruct.Mode = GPIO_MODE_OUTPUT_PP;
  GPIO_InitStruct.Pull = GPIO_NOPULL;
  GPIO_InitStruct.Speed = GPIO_SPEED_FREQ_LOW;
  HAL_GPIO_Init(GPIOD, &GPIO_InitStruct);

}

void Error_Handler(void)
{
  __disable_irq();
  while (1)
  {
  }
}
